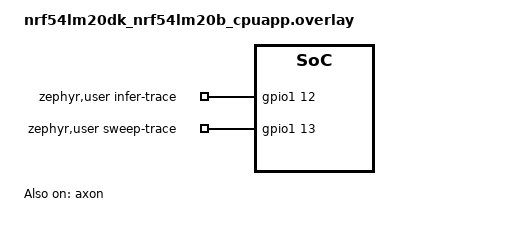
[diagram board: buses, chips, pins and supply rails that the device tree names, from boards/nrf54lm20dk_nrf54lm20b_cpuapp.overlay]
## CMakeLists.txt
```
cmake_minimum_required(VERSION 3.20.0)

find_package(Zephyr REQUIRED HINTS $ENV{ZEPHYR_BASE})
project(multi_chirp_npu)

# generated/ + generated_data/ sit next to this file; resolve includes + .incbin from here
target_compile_options(app PRIVATE -Wa,-I${CMAKE_CURRENT_SOURCE_DIR})
target_include_directories(app PRIVATE ${CMAKE_CURRENT_SOURCE_DIR} src)

target_sources(app PRIVATE
    src/main.c
    src/sample_input.c
    src/mel_compute.c
    src/mel_fft_axon.c
)

if(DEFINED ENV{MEL_FFT_CPU})
    target_compile_definitions(app PRIVATE MEL_FFT_CPU)
endif()
if(DEFINED ENV{MEL_BENCH_ONLY})
    target_compile_definitions(app PRIVATE MEL_BENCH_ONLY)
endif()
if(DEFINED ENV{ENERGY_TRACE})
    target_compile_definitions(app PRIVATE ENERGY_TRACE)
endif()
```

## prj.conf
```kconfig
CONFIG_NCS_SAMPLES_DEFAULTS=y

# Sized via the per-model nrf_axon_model_current_model_.h asserts; 360000 leaves
# plenty of headroom for any of our mel-input models on the nRF54LM20B's 511 KB.
CONFIG_NRF_AXON=y
CONFIG_NRF_AXON_INTERLAYER_BUFFER_SIZE=360000
CONFIG_NRF_AXON_PSUM_BUFFER_SIZE=0

CONFIG_PICOLIBC_IO_FLOAT=y
CONFIG_MAIN_STACK_SIZE=4096

# Hardware FPU — without it the mel FFT/sqrtf/logf are soft-float (10-30x slower)
CONFIG_FPU=y

# CMSIS-DSP real FFT (arm_rfft_fast_f32) for the CPU mel preprocessing
CONFIG_CMSIS_DSP=y
CONFIG_CMSIS_DSP_TRANSFORM=y
```

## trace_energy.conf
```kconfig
# Extra config for ENERGY_TRACE builds (make trace=1): the GPIO driver for
# the PPK2 trace pins. Normal builds don't pull this in.
CONFIG_GPIO=y
```

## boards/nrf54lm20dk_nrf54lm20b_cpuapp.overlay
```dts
&axon {
    status = "okay";
};

/* PPK2 trace pins (ENERGY_TRACE builds only; unreferenced otherwise).
 * P1.12/P1.13 are free on the GPIO_P1 header — same wiring as nrf-blinky
 * and the Rust bench: D0 = one inference, D1 = the whole sweep. */
/ {
    zephyr,user {
        infer-trace-gpios = <&gpio1 12 GPIO_ACTIVE_HIGH>;
        sweep-trace-gpios = <&gpio1 13 GPIO_ACTIVE_HIGH>;
    };
};
```

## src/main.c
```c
#include <assert.h>  // static_assert in the axon-generated model header

#include <zephyr/kernel.h>
#include <zephyr/sys/printk.h>

#include <axon/nrf_axon_platform.h>
#ifndef MEL_BENCH_ONLY
#include <drivers/axon/nrf_axon_nn_infer.h>
#include "generated/nrf_axon_model_current_model_.h"
#endif
#include "sample_input.h"
#include "mel_compute.h"

/* ENERGY_TRACE (make trace=1): PPK2 bracket pins from the board overlay —
 * D0 high around each inference, D1 around the sweep. Timing + printk stay
 * as-is (they sit outside D0), so a trace run still prints latencies. */
#ifdef ENERGY_TRACE
#include <zephyr/drivers/gpio.h>

#define TRACE_NODE DT_PATH(zephyr_user)
static const struct gpio_dt_spec trace_d0 = GPIO_DT_SPEC_GET(TRACE_NODE, infer_trace_gpios);
static const struct gpio_dt_spec trace_d1 = GPIO_DT_SPEC_GET(TRACE_NODE, sweep_trace_gpios);

static int trace_init(void)
{
	if (!gpio_is_ready_dt(&trace_d0) || !gpio_is_ready_dt(&trace_d1) ||
	    gpio_pin_configure_dt(&trace_d0, GPIO_OUTPUT_INACTIVE) ||
	    gpio_pin_configure_dt(&trace_d1, GPIO_OUTPUT_INACTIVE)) {
		printk("trace gpio init failed\n");
		return -1;
	}
	return 0;
}

#define TRACE_SET(pin, v) gpio_pin_set_dt(&(pin), (v))
#else
#define TRACE_SET(pin, v)
#endif

#define N_RUNS 10
#define ull unsigned long long

#ifdef MEL_FFT_CPU
#define FFT_BACKEND "cpu"
#else
#define FFT_BACKEND "axon"
#endif

static int8_t mel_buf_int8[MEL_TARGET_FRAMES * MEL_NUM_BINS];

static uint64_t cycles_to_us(uint64_t cycles)
{
	return k_cyc_to_ns_floor64(cycles) / 1000;
}

static void print_avg_steps(void)
{
	printk("avg step: framing %llu us, fft %llu us, mag %llu us, mel %llu us, logq %llu us\n",
	       (ull)(cycles_to_us(mel_framing_cyc) / N_RUNS),
	       (ull)(cycles_to_us(mel_fft_cyc) / N_RUNS),
	       (ull)(cycles_to_us(mel_mag_cyc) / N_RUNS),
	       (ull)(cycles_to_us(mel_mel_cyc) / N_RUNS),
	       (ull)(cycles_to_us(mel_logq_cyc) / N_RUNS));
}

int main(void)
{
	if (nrf_axon_platform_init()) {
		printk("axon init failed\n");
		return -1;
	}

#ifdef ENERGY_TRACE
	if (trace_init()) {
		return -1;
	}
#endif

	const int16_t *audio = g_sample_clip_audio;
	mel_compute_init();

#ifdef MEL_BENCH_ONLY
	printk("frames=%d bins=%d fft=%s (spectro-only)\n",
	       MEL_TARGET_FRAMES, MEL_NUM_BINS, FFT_BACKEND);

	if (mel_compute(audio, mel_buf_int8)) {
		printk("warmup mel_compute failed\n");
		return -1;
	}
	mel_reset_steps();

	uint64_t total_pre = 0;
	TRACE_SET(trace_d1, 1); /* D1 high — whole sweep */
	for (int i = 0; i < N_RUNS; i++) {
		const uint32_t t0 = k_cycle_get_32();
		TRACE_SET(trace_d0, 1); /* D0 high — one preprocess */
		const int mel_err = mel_compute(audio, mel_buf_int8);
		TRACE_SET(trace_d0, 0);
		if (mel_err) {
			printk("run %d: mel_compute failed\n", i);
			return -1;
		}
		const uint64_t pre = cycles_to_us(k_cycle_get_32() - t0);
		total_pre += pre;
		printk("run %d : pre %llu us\n", i, (ull)pre);
#ifdef ENERGY_TRACE
		k_sleep(K_MSEC(100)); /* pulse separation for the PPK2 capture */
#endif
	}
	TRACE_SET(trace_d1, 0);
	printk("avg preprocess: %llu us (%d runs)\n", (ull)(total_pre / N_RUNS), N_RUNS);
	print_avg_steps();
#else
	if (nrf_axon_nn_model_init_vars(&model_current_model)) {
		printk("axon init failed\n");
		return -1;
	}

	const int n_out = model_current_model.output_dimensions.width;
	const float s = (float)model_current_model.output_dequant_mult /
	                (float)(1U << model_current_model.output_dequant_round);
	const int32_t zp = model_current_model.output_dequant_zp;

	printk("model=%s frames=%d bins=%d outputs=%d targets=%d fft=%s\n",
	       model_current_model.model_name, MEL_TARGET_FRAMES, MEL_NUM_BINS,
	       n_out, NUM_TARGET_CLASSES, FFT_BACKEND);

	int32_t out_q[MAX_MODEL_OUTPUTS];
	if (n_out > MAX_MODEL_OUTPUTS) {
		printk("model has %d outputs, only %d allocated\n", n_out, MAX_MODEL_OUTPUTS);
		return -1;
	}

	if (mel_compute(audio, mel_buf_int8)) {
		printk("warmup mel_compute failed\n");
		return -1;
	}
	nrf_axon_nn_model_infer_sync(&model_current_model, mel_buf_int8, (int8_t *)out_q);

	uint64_t total_pre = 0;
	uint64_t total_inf = 0;
	mel_reset_steps();

	TRACE_SET(trace_d1, 1); /* D1 high — whole sweep */
	for (int i = 0; i < N_RUNS; i++) {
		const uint32_t t0 = k_cycle_get_32();
		if (mel_compute(audio, mel_buf_int8)) {
			printk("run %d: mel_compute failed\n", i);
			return -1;
		}
		const uint32_t t1 = k_cycle_get_32();
		TRACE_SET(trace_d0, 1); /* D0 high — inference only */
		nrf_axon_nn_model_infer_sync(&model_current_model, mel_buf_int8, (int8_t *)out_q);
		TRACE_SET(trace_d0, 0);
		const uint32_t t2 = k_cycle_get_32();

		const uint64_t pre = cycles_to_us(t1 - t0);
		const uint64_t inf = cycles_to_us(t2 - t1);
		total_pre += pre;
		total_inf += inf;
		printk("run %d : pre %llu us inf %llu us\n", i, (ull)pre, (ull)inf);
#ifdef ENERGY_TRACE
		k_sleep(K_MSEC(100)); /* idle gap: separates pulses, shows the floor */
#endif
	}
	TRACE_SET(trace_d1, 0);

	printk("per-class scores:\n");
	for (int c = 0; c < NUM_TARGET_CLASSES; c++) {
		const float v = (float)(out_q[c] - zp) * s;
		printk("  %s : %.3f\n", g_class_names[c], (double)v);
	}

	printk("avg preprocess: %llu us (%d runs)\n", (ull)(total_pre / N_RUNS), N_RUNS);
	print_avg_steps();
	printk("avg inference: %llu us (%d runs)\n", (ull)(total_inf / N_RUNS), N_RUNS);
#endif

	printk("DONE\n");
	return 0;
}
```

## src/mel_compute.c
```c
#include <math.h>
#include <stdint.h>

#include <zephyr/kernel.h>
#ifdef MEL_FFT_CPU
#include <arm_math.h>
#endif

#include "sample_input.h"
#include "mel_compute.h"

#define MEL_SAMPLE_RATE 16000.0
#define MEL_MIN_HZ 2500.0
#define MEL_MAX_HZ 8000.0
#define MEL_EPS 1e-6f
#define MEL_PI 3.14159265358979323846f
#define INV_SAMPLE (1.0f / 32768.0f)

_Static_assert((1 << MEL_FFT_LOG2) == MEL_FRAME_LENGTH, "FFT log2 must match frame length");
_Static_assert(MEL_FFT_BINS == MEL_FRAME_LENGTH / 2, "fft bins must be frame length / 2");

static float hann[MEL_FRAME_LENGTH];
static uint16_t mel_fft_bin[2 * MEL_FFT_BINS];
static uint8_t mel_out_bin[2 * MEL_FFT_BINS];
static float mel_weight[2 * MEL_FFT_BINS];
static int mel_filters_len;

static float frame[MEL_FRAME_LENGTH];
static float spec_re[MEL_FRAME_LENGTH];
static float spec_im[MEL_FRAME_LENGTH];
static float mag[MEL_FFT_BINS];
static float mel_energy[MEL_NUM_BINS];

uint64_t mel_framing_cyc, mel_fft_cyc, mel_mag_cyc, mel_mel_cyc, mel_logq_cyc;

#ifdef MEL_FFT_CPU
static arm_rfft_fast_instance_f32 fft_inst;
static float fft_spec[MEL_FRAME_LENGTH];
#else
#define FFT_FULLSCALE (1u << 22)
static const float fft_recover = (float)MEL_FRAME_LENGTH / (float)FFT_FULLSCALE;
static const int32_t int24_cap = (1 << 23) - 1;
static int32_t fft_in[2 * MEL_FRAME_LENGTH];
static int32_t fft_out[2 * MEL_FRAME_LENGTH];
#endif

void mel_reset_steps(void)
{
	mel_framing_cyc = mel_fft_cyc = mel_mag_cyc = mel_mel_cyc = mel_logq_cyc = 0;
}

static int mel_edge(int i, double low_mel, double high_mel)
{
	double frac = (double)i / (double)(MEL_NUM_BINS + 1);
	double mel = low_mel + frac * (high_mel - low_mel);
	double hz = 700.0 * (pow(10.0, mel / 2595.0) - 1.0);
	int bin = (int)((MEL_FRAME_LENGTH + 1.0) * hz / MEL_SAMPLE_RATE);
	return bin >= MEL_FFT_BINS ? MEL_FFT_BINS - 1 : bin;
}

void mel_compute_init(void)
{
#ifdef MEL_FFT_CPU
	arm_rfft_fast_init_f32(&fft_inst, MEL_FRAME_LENGTH);
#endif
	for (int i = 0; i < MEL_FRAME_LENGTH; i++) {
		hann[i] = 0.5f - 0.5f * cosf(2.0f * MEL_PI * i / (MEL_FRAME_LENGTH - 1));
	}

	const double low_mel = 2595.0 * log10(1.0 + MEL_MIN_HZ / 700.0);
	const double high_mel = 2595.0 * log10(1.0 + MEL_MAX_HZ / 700.0);
	int e = 0;
	for (int m = 0; m < MEL_NUM_BINS; m++) {
		int left = mel_edge(m, low_mel, high_mel);
		int center = mel_edge(m + 1, low_mel, high_mel);
		int right = mel_edge(m + 2, low_mel, high_mel);
		for (int k = left; k < center; k++) {
			mel_fft_bin[e] = k;
			mel_out_bin[e] = m;
			mel_weight[e] = (float)(k - left) / (float)(center - left > 0 ? center - left : 1);
			e++;
		}
		for (int k = center; k < right; k++) {
			mel_fft_bin[e] = k;
			mel_out_bin[e] = m;
			mel_weight[e] = (float)(right - k) / (float)(right - center > 0 ? right - center : 1);
			e++;
		}
	}
	mel_filters_len = e;
}

int mel_compute(const int16_t *audio, int8_t *out_int8)
{
	const float in_scale = g_input_quant_scale;
	const int32_t in_zp = g_input_quant_zp;

	for (int f = 0; f < MEL_TARGET_FRAMES; f++) {
		const int base = f * MEL_FRAME_STEP;

		const uint32_t t0 = k_cycle_get_32();
		for (int n = 0; n < MEL_FRAME_LENGTH; n++) {
			int idx = base + n;
			float s = idx < MEL_AUDIO_LEN ? (float)audio[idx] : 0.0f;
			frame[n] = s * hann[n] * INV_SAMPLE;
		}
		const uint32_t t1 = k_cycle_get_32();

#ifdef MEL_FFT_CPU
		arm_rfft_fast_f32(&fft_inst, frame, fft_spec, 0);
		spec_re[0] = fft_spec[0];  // DC; Nyquist (fft_spec[1]) is bin MEL_FFT_BINS, unused
		spec_im[0] = 0.0f;
		for (int k = 1; k < MEL_FFT_BINS; k++) {
			spec_re[k] = fft_spec[2 * k];
			spec_im[k] = fft_spec[2 * k + 1];
		}
#else
		for (int n = 0; n < MEL_FRAME_LENGTH; n++) {
			int32_t v = (int32_t)lroundf(frame[n] * (float)FFT_FULLSCALE);
			if (v > int24_cap) v = int24_cap;
			if (v < -int24_cap) v = -int24_cap;
			fft_in[2 * n] = v;
		}
		int err = mel_fft_axon(fft_in, fft_out);
		if (err) return err;
		for (int k = 0; k < MEL_FFT_BINS; k++) {
			spec_re[k] = (float)fft_out[2 * k] * fft_recover;
			spec_im[k] = (float)fft_out[2 * k + 1] * fft_recover;
		}
#endif
		const uint32_t t2 = k_cycle_get_32();

		for (int k = 0; k < MEL_FFT_BINS; k++) {
			mag[k] = sqrtf(spec_re[k] * spec_re[k] + spec_im[k] * spec_im[k]);
		}
		const uint32_t t3 = k_cycle_get_32();

		for (int m = 0; m < MEL_NUM_BINS; m++) {
			mel_energy[m] = 0.0f;
		}
		for (int i = 0; i < mel_filters_len; i++) {
			mel_energy[mel_out_bin[i]] += mag[mel_fft_bin[i]] * mel_weight[i];
		}
		const uint32_t t4 = k_cycle_get_32();

		int8_t *row = &out_int8[f * MEL_NUM_BINS];
		for (int m = 0; m < MEL_NUM_BINS; m++) {
			int32_t q = (int32_t)lroundf(logf(mel_energy[m] + MEL_EPS) / in_scale) + in_zp;
			if (q < -128) q = -128;
			if (q > 127) q = 127;
			row[m] = (int8_t)q;
		}
		const uint32_t t5 = k_cycle_get_32();

		mel_framing_cyc += (uint32_t)(t1 - t0);
		mel_fft_cyc += (uint32_t)(t2 - t1);
		mel_mag_cyc += (uint32_t)(t3 - t2);
		mel_mel_cyc += (uint32_t)(t4 - t3);
		mel_logq_cyc += (uint32_t)(t5 - t4);
	}
	return 0;
}
```

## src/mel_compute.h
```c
#pragma once

#include <stdint.h>

#include "generated_data/sample_input_meta.h"  // MEL_FFT_LOG2, frame/bin sizes

void mel_compute_init(void);
int mel_compute(const int16_t *audio, int8_t *out_int8);
int mel_fft_axon(const int32_t *complex_in, int32_t *complex_out);

extern uint64_t mel_framing_cyc, mel_fft_cyc, mel_mag_cyc, mel_mel_cyc, mel_logq_cyc;
void mel_reset_steps(void);
```

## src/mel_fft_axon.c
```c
#include <stdbool.h>
#include <stdint.h>

#include <drivers/axon/nrf_axon_dsp_intrinsics.h>
#include <drivers/axon/nrf_axon_driver.h>

#include "mel_compute.h"

int mel_fft_axon(const int32_t *complex_in, int32_t *complex_out)
{
	return axon_fft_24(complex_in, complex_out, MEL_FFT_LOG2, true, true,
			   NRF_AXON_SYNC_MODE_BLOCKING_POLLING, true);
}
```

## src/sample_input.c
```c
#include "sample_input.h"
#include "generated_data/class_names.h"

#define INCBIN(symbol, file, align) \
	__asm__(".section .rodata." #symbol ",\"a\",%progbits\n" \
		".balign " #align "\n" \
		".global " #symbol "\n" \
		".type " #symbol ",%object\n" \
		#symbol ":\n" \
		".incbin \"" file "\"\n" \
		".size " #symbol ", . - " #symbol "\n" \
		".previous\n")

INCBIN(g_sample_clip_audio, "generated_data/sample_audio.bin", 2);

const float g_input_quant_scale = MEL_INPUT_QUANT_SCALE;
const int32_t g_input_quant_zp = MEL_INPUT_QUANT_ZP;

const char *const g_class_names[NUM_TARGET_CLASSES] = CLASS_NAMES_INIT;
```

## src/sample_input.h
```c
#pragma once

#include <stdint.h>
#include <stddef.h>

#include "generated_data/sample_input_meta.h"

extern const int16_t g_sample_clip_audio[];
extern const char *const g_class_names[NUM_TARGET_CLASSES];

extern const float g_input_quant_scale;
extern const int32_t g_input_quant_zp;
```
